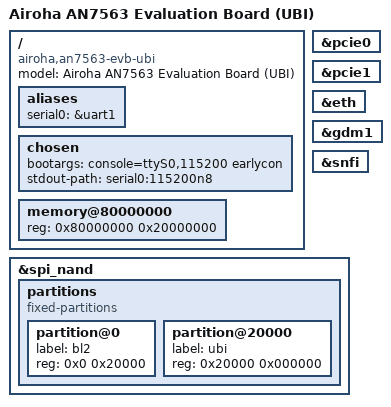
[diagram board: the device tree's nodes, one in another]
// SPDX-License-Identifier: (GPL-2.0-only OR BSD-2-Clause)
/dts-v1/;

#include "an7563.dtsi"

/ {
	model = "Airoha AN7563 Evaluation Board (UBI)";
	compatible = "airoha,an7563-evb-ubi", "airoha,an7563", "airoha,an7552";

	aliases {
		serial0 = &uart1;
	};

	chosen {
		bootargs = "console=ttyS0,115200 earlycon";
		stdout-path = "serial0:115200n8";
	};

	memory@80000000 {
		device_type = "memory";
		reg = <0x80000000 0x20000000>;
	};
};

&pcie0 {
	status = "okay";
};

&pcie1 {
	status = "okay";
};

&eth {
	status = "okay";
};

&gdm1 {
	status = "okay";
};

&snfi {
	status = "okay";
};

&spi_nand {
	partitions {
		compatible = "fixed-partitions";
		#address-cells = <1>;
		#size-cells = <1>;

		partition@0 {
			label = "bl2";
			reg = <0x0 0x20000>;
		};

		partition@20000 {
			label = "ubi";
			reg = <0x20000 0x000000>;
		};
	};
};
